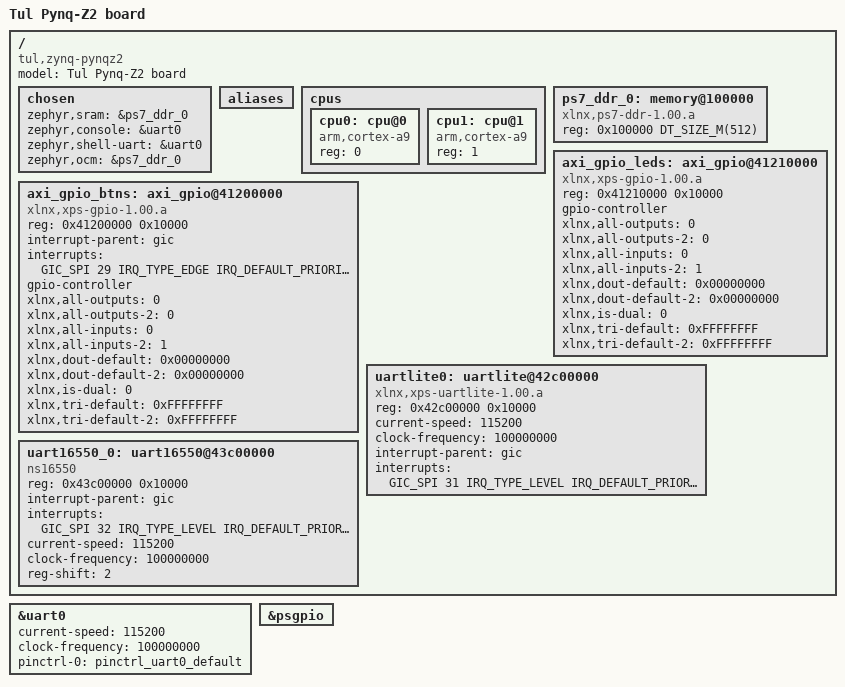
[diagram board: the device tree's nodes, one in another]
/*
 * Copyright (c) 2022 Henrik Brix Andersen <henrik@brixandersen.dk>
 *
 * SPDX-License-Identifier: Apache-2.0
 */

/dts-v1/;
#include <xilinx/zynq7000.dtsi>
#include <zephyr/dt-bindings/gpio/gpio.h>
#include <zephyr/dt-bindings/input/input-event-codes.h>
#include <zephyr/dt-bindings/interrupt-controller/arm-gic.h>
#include "pynqz2-pinctrl.dtsi"

/ {
	model = "Tul Pynq-Z2 board";
	compatible = "tul,zynq-pynqz2", "xlnx,zynq-7000";

	#address-cells = <1>;
	#size-cells = <1>;

	chosen {
		zephyr,sram = &ps7_ddr_0;
		zephyr,console = &uart0;
		zephyr,shell-uart = &uart0;
		zephyr,ocm = &ps7_ddr_0;
	};

	aliases {
		//     led0 = &ld_mio;
		//     sw0 = &btn4;
		//     sw1 = &btn5;
	};

	cpus {
		#address-cells = <1>;
		#size-cells = <0>;

		cpu0: cpu@0 {
			device_type = "cpu";
			compatible = "arm,cortex-a9";
			reg = <0>;
		};

		cpu1: cpu@1 {
			device_type = "cpu";
			compatible = "arm,cortex-a9";
			reg = <1>;
		};
	};

	ps7_ddr_0: memory@100000 {
		compatible = "xlnx,ps7-ddr-1.00.a";
		reg = <0x100000 DT_SIZE_M(512)>;
	};

	axi_gpio_btns: axi_gpio@41200000 {
		compatible = "xlnx,xps-gpio-1.00.a";
		status = "okay";
		reg = <0x41200000 0x10000>;
		interrupt-parent = <&gic>;
		interrupts = <GIC_SPI 29 IRQ_TYPE_EDGE IRQ_DEFAULT_PRIORITY>;
		gpio-controller;
		#gpio-cells = <2>;
		xlnx,all-outputs = <0>;
		xlnx,all-outputs-2 = <0>;
		xlnx,all-inputs = <0>;
		xlnx,all-inputs-2 = <1>;
		xlnx,dout-default = <0x00000000>;
		xlnx,dout-default-2 = <0x00000000>;
		xlnx,is-dual = <0>;
		xlnx,tri-default = <0xFFFFFFFF>;
		xlnx,tri-default-2 = <0xFFFFFFFF>;
	};

	axi_gpio_leds: axi_gpio@41210000 {
		compatible = "xlnx,xps-gpio-1.00.a";
		status = "okay";
		reg = <0x41210000 0x10000>;
		gpio-controller;
		#gpio-cells = <2>;
		xlnx,all-outputs = <0>;
		xlnx,all-outputs-2 = <0>;
		xlnx,all-inputs = <0>;
		xlnx,all-inputs-2 = <1>;
		xlnx,dout-default = <0x00000000>;
		xlnx,dout-default-2 = <0x00000000>;
		xlnx,is-dual = <0>;
		xlnx,tri-default = <0xFFFFFFFF>;
		xlnx,tri-default-2 = <0xFFFFFFFF>;
	};

	uartlite0: uartlite@42c00000 {
		// TODO: interrupt bring up
		compatible = "xlnx,xps-uartlite-1.00.a";
		status = "okay";
		reg = <0x42c00000 0x10000>;
		current-speed = <115200>;
		clock-frequency = <100000000>;
		interrupt-parent = <&gic>;
		interrupts = <GIC_SPI 31 IRQ_TYPE_LEVEL IRQ_DEFAULT_PRIORITY>;
		interrupt-names = "irq_0";
	};

	uart16550_0: uart16550@43c00000 {
		compatible = "ns16550";
		status = "okay";
		reg = <0x43c00000 0x10000>;
		interrupt-parent = <&gic>;
		interrupts = <GIC_SPI 32 IRQ_TYPE_LEVEL IRQ_DEFAULT_PRIORITY>;
		current-speed = <115200>;
		clock-frequency = <100000000>;
		interrupt-names = "irq_0";
		reg-shift = <2>; // aligned to 32bits system
	};
};

&uart0 {
	status = "okay";
	current-speed = <115200>;
	clock-frequency = <100000000>;
	pinctrl-0 = <&pinctrl_uart0_default>;
	pinctrl-names = "default";
};

&psgpio {
	status = "okay";
};
